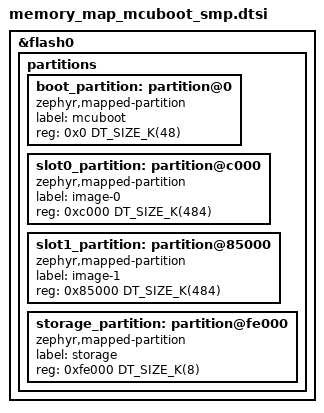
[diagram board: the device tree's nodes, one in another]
/*
 * Copyright (c) 2026 Nordic Semiconductor ASA
 *
 * SPDX-License-Identifier: LicenseRef-Nordic-5-Clause
 */

&flash0 {
	/delete-node/ partitions;

	partitions {
		#address-cells = <1>;
		#size-cells = <1>;
		ranges;

		boot_partition: partition@0 {
			compatible = "zephyr,mapped-partition";
			label = "mcuboot";
			reg = <0x0 DT_SIZE_K(48)>;
		};

		slot0_partition: partition@c000 {
			compatible = "zephyr,mapped-partition";
			label = "image-0";
			reg = <0xc000 DT_SIZE_K(484)>;
		};

		slot1_partition: partition@85000 {
			compatible = "zephyr,mapped-partition";
			label = "image-1";
			reg = <0x85000 DT_SIZE_K(484)>;
		};

		storage_partition: partition@fe000 {
			compatible = "zephyr,mapped-partition";
			label = "storage";
			reg = <0xfe000 DT_SIZE_K(8)>;
		};
	};
};
